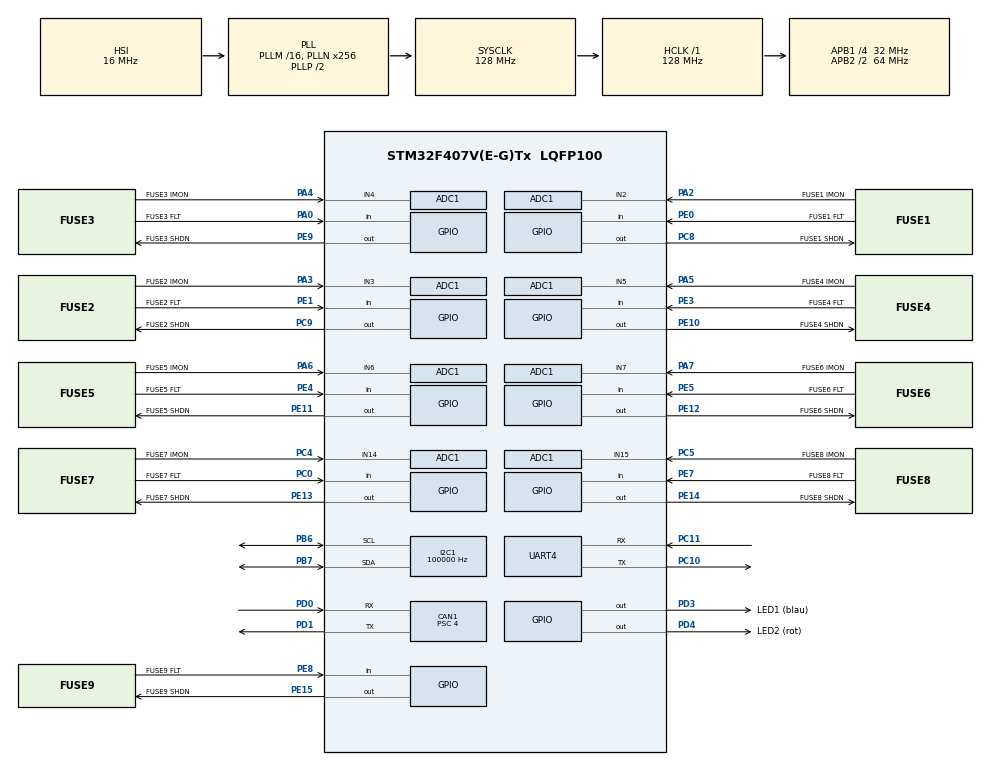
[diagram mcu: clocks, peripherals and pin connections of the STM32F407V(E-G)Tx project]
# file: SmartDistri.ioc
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ADC1.Channel-10\#ChannelRegularConversion=ADC_CHANNEL_14
ADC1.Channel-11\#ChannelRegularConversion=ADC_CHANNEL_15
ADC1.Channel-4\#ChannelRegularConversion=ADC_CHANNEL_2
ADC1.Channel-5\#ChannelRegularConversion=ADC_CHANNEL_3
ADC1.Channel-6\#ChannelRegularConversion=ADC_CHANNEL_4
ADC1.Channel-7\#ChannelRegularConversion=ADC_CHANNEL_5
ADC1.Channel-8\#ChannelRegularConversion=ADC_CHANNEL_6
ADC1.Channel-9\#ChannelRegularConversion=ADC_CHANNEL_7
ADC1.ClockPrescaler=ADC_CLOCK_SYNC_PCLK_DIV8
ADC1.ContinuousConvMode=ENABLE
ADC1.DMAContinuousRequests=ENABLE
ADC1.DiscontinuousConvMode=DISABLE
ADC1.EOCSelection=ADC_EOC_SEQ_CONV
ADC1.NbrOfConversion=8
ADC1.NbrOfConversionFlag=1
ADC1.Rank-10\#ChannelRegularConversion=7
ADC1.Rank-11\#ChannelRegularConversion=8
ADC1.Rank-4\#ChannelRegularConversion=1
ADC1.Rank-5\#ChannelRegularConversion=2
ADC1.Rank-6\#ChannelRegularConversion=3
ADC1.Rank-7\#ChannelRegularConversion=4
ADC1.Rank-8\#ChannelRegularConversion=5
ADC1.Rank-9\#ChannelRegularConversion=6
ADC1.SamplingTime-10\#ChannelRegularConversion=ADC_SAMPLETIME_3CYCLES
ADC1.SamplingTime-11\#ChannelRegularConversion=ADC_SAMPLETIME_3CYCLES
ADC1.SamplingTime-4\#ChannelRegularConversion=ADC_SAMPLETIME_3CYCLES
ADC1.SamplingTime-5\#ChannelRegularConversion=ADC_SAMPLETIME_3CYCLES
ADC1.SamplingTime-6\#ChannelRegularConversion=ADC_SAMPLETIME_3CYCLES
ADC1.SamplingTime-7\#ChannelRegularConversion=ADC_SAMPLETIME_3CYCLES
ADC1.SamplingTime-8\#ChannelRegularConversion=ADC_SAMPLETIME_3CYCLES
ADC1.SamplingTime-9\#ChannelRegularConversion=ADC_SAMPLETIME_3CYCLES
ADC1.master=1
CAN1.BS1=CAN_BS1_13TQ
CAN1.BS2=CAN_BS2_2TQ
CAN1.CalculateTimeQuantum=125.0
CAN1.Mode=CAN_MODE_LOOPBACK
CAN1.Prescaler=4
Dma.ADC1.0.Direction=DMA_PERIPH_TO_MEMORY
Dma.ADC1.0.FIFOMode=DMA_FIFOMODE_DISABLE
Dma.ADC1.0.Instance=DMA2_Stream0
Dma.ADC1.0.MemDataAlignment=DMA_MDATAALIGN_WORD
Dma.ADC1.0.MemInc=DMA_MINC_ENABLE
Dma.ADC1.0.Mode=DMA_CIRCULAR
Dma.ADC1.0.PeriphDataAlignment=DMA_PDATAALIGN_WORD
Dma.ADC1.0.PeriphInc=DMA_PINC_DISABLE
Dma.ADC1.0.Priority=DMA_PRIORITY_LOW
Dma.I2C1_RX.1.Direction=DMA_PERIPH_TO_MEMORY
Dma.I2C1_RX.1.FIFOMode=DMA_FIFOMODE_DISABLE
Dma.I2C1_RX.1.Instance=DMA1_Stream0
Dma.I2C1_RX.1.MemDataAlignment=DMA_MDATAALIGN_BYTE
Dma.I2C1_RX.1.MemInc=DMA_MINC_ENABLE
Dma.I2C1_RX.1.Mode=DMA_CIRCULAR
Dma.I2C1_RX.1.PeriphDataAlignment=DMA_PDATAALIGN_BYTE
Dma.I2C1_RX.1.PeriphInc=DMA_PINC_DISABLE
Dma.I2C1_RX.1.Priority=DMA_PRIORITY_LOW
Dma.Request0=ADC1
Dma.Request1=I2C1_RX
I2C1.ClockSpeed=100000
I2C1.I2C_Mode=I2C_Standard
Mcu.Family=STM32F4
Mcu.Name=STM32F407V(E-G)Tx
Mcu.Package=LQFP100
NVIC.CAN1_RX0_IRQn=true\:0\:0\:false\:false\:true\:true\:true
NVIC.CAN1_TX_IRQn=true\:0\:0\:false\:false\:true\:true\:true
NVIC.DMA1_Stream0_IRQn=true\:0\:0\:false\:false\:true\:false\:true
NVIC.DMA2_Stream0_IRQn=true\:0\:0\:false\:false\:true\:false\:true
NVIC.PriorityGroup=NVIC_PRIORITYGROUP_4
NVIC.TIM1_UP_TIM10_IRQn=true\:0\:0\:false\:false\:true\:true\:true
PA0-WKUP.GPIO_Label=FUSE3 FLT
PA0-WKUP.GPIO_PuPd=GPIO_PULLDOWN
PA0-WKUP.Signal=GPIO_Input
PA13.Signal=SYS_JTMS-SWDIO
PA14.Signal=SYS_JTCK-SWCLK
PA15.Signal=SYS_JTDI
PA2.GPIO_Label=FUSE1 IMON
PA2.Signal=ADCx_IN2
PA3.GPIO_Label=FUSE2 IMON
PA3.Signal=ADCx_IN3
PA4.GPIO_Label=FUSE3 IMON
PA4.Signal=ADCx_IN4
PA5.GPIO_Label=FUSE4 IMON
PA5.Signal=ADCx_IN5
PA6.GPIO_Label=FUSE5 IMON
PA6.Signal=ADCx_IN6
PA7.GPIO_Label=FUSE6 IMON
PA7.Signal=ADCx_IN7
PB6.Mode=I2C
PB6.Signal=I2C1_SCL
PB7.Mode=I2C
PB7.Signal=I2C1_SDA
PC0.GPIO_Label=FUSE7 FLT
PC0.GPIO_PuPd=GPIO_PULLDOWN
PC0.Signal=GPIO_Input
PC10.Mode=Asynchronous
PC10.Signal=UART4_TX
PC11.Mode=Asynchronous
PC11.Signal=UART4_RX
PC4.GPIO_Label=FUSE7 IMON
PC4.Signal=ADCx_IN14
PC5.GPIO_Label=FUSE8 IMON
PC5.Signal=ADCx_IN15
PC8.GPIO_Label=FUSE1 SHDN
PC8.Signal=GPIO_Output
PC9.GPIO_Label=FUSE2 SHDN
PC9.Signal=GPIO_Output
PD0.Mode=Master
PD0.Signal=CAN1_RX
PD1.Mode=Master
PD1.Signal=CAN1_TX
PD3.GPIO_Label=LED1 (blau)
PD3.Signal=GPIO_Output
PD4.GPIO_Label=LED2 (rot)
PD4.Signal=GPIO_Output
PE0.GPIO_Label=FUSE1 FLT
PE0.GPIO_PuPd=GPIO_PULLDOWN
PE0.Signal=GPIO_Input
PE1.GPIO_Label=FUSE2 FLT
PE1.GPIO_PuPd=GPIO_PULLDOWN
PE1.Signal=GPIO_Input
PE10.GPIO_Label=FUSE4 SHDN
PE10.Signal=GPIO_Output
PE11.GPIO_Label=FUSE5 SHDN
PE11.GPIO_PuPd=GPIO_NOPULL
PE11.PinState=GPIO_PIN_SET
PE11.Signal=GPIO_Output
PE12.GPIO_Label=FUSE6 SHDN
PE12.Signal=GPIO_Output
PE13.GPIO_Label=FUSE7 SHDN
PE13.Signal=GPIO_Output
PE14.GPIO_Label=FUSE8 SHDN
PE14.Signal=GPIO_Output
PE15.GPIO_Label=FUSE9 SHDN
PE15.Signal=GPIO_Output
PE3.GPIO_Label=FUSE4 FLT
PE3.GPIO_PuPd=GPIO_PULLDOWN
PE3.Signal=GPIO_Input
PE4.GPIO_Label=FUSE5 FLT
PE4.GPIO_PuPd=GPIO_PULLDOWN
PE4.Signal=GPIO_Input
PE5.GPIO_Label=FUSE6 FLT
PE5.GPIO_PuPd=GPIO_PULLDOWN
PE5.Signal=GPIO_Input
PE7.GPIO_Label=FUSE8 FLT
PE7.GPIO_PuPd=GPIO_PULLDOWN
PE7.Signal=GPIO_Input
PE8.GPIO_Label=FUSE9 FLT
PE8.Signal=GPIO_Input
PE9.GPIO_Label=FUSE3 SHDN
PE9.Signal=GPIO_Output
ProjectManager.HeapSize=0x200
ProjectManager.StackSize=0x400
ProjectManager.TargetToolchain=STM32CubeIDE
RCC.48MHZClocksFreq_Value=64000000
RCC.AHBFreq_Value=128000000
RCC.APB1CLKDivider=RCC_HCLK_DIV4
RCC.APB1Freq_Value=32000000
RCC.APB1TimFreq_Value=64000000
RCC.APB2CLKDivider=RCC_HCLK_DIV2
RCC.APB2Freq_Value=64000000
RCC.APB2TimFreq_Value=128000000
RCC.CortexFreq_Value=128000000
RCC.HCLKFreq_Value=128000000
RCC.HSE_VALUE=25000000
RCC.HSI_VALUE=16000000
RCC.LSE_VALUE=32768
RCC.PLLN=256
RCC.SYSCLKFreq_VALUE=128000000
RCC.SYSCLKSource=RCC_SYSCLKSOURCE_PLLCLK
RCC.VCOOutputFreq_Value=256000000
SH.ADCx_IN14.0=ADC1_IN14,IN14
SH.ADCx_IN15.0=ADC1_IN15,IN15
SH.ADCx_IN2.0=ADC1_IN2,IN2
SH.ADCx_IN3.0=ADC1_IN3,IN3
SH.ADCx_IN4.0=ADC1_IN4,IN4
SH.ADCx_IN5.0=ADC1_IN5,IN5
SH.ADCx_IN6.0=ADC1_IN6,IN6
SH.ADCx_IN7.0=ADC1_IN7,IN7
TIM1.Period=400
TIM1.Prescaler=64000
UART4.VirtualMode=Asynchronous
VP_TIM1_VS_ClockSourceINT.Mode=Internal
VP_TIM1_VS_ClockSourceITR.Mode=TriggerSource_ITR0
board=custom

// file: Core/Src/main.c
/* USER CODE BEGIN Header */
/**
  ******************************************************************************
  * @file           : main.c
  * @brief          : Main program body
  ******************************************************************************
  * @attention
  *
  * <h2><center>&copy; Copyright (c) 2020 STMicroelectronics.
  * All rights reserved.</center></h2>
  *
  * This software component is licensed by ST under BSD 3-Clause license,
  * the "License"; You may not use this file except in compliance with the
  * License. You may obtain a copy of the License at:
  *                        opensource.org/licenses/BSD-3-Clause
  *
  ******************************************************************************
  */
/* USER CODE END Header */
#include "main.h"

/* USER CODE BEGIN Includes */
#include "smart_distri.h"
/* USER CODE END Includes */

ADC_HandleTypeDef hadc1;
DMA_HandleTypeDef hdma_adc1;

CAN_HandleTypeDef hcan1;

I2C_HandleTypeDef hi2c1;
DMA_HandleTypeDef hdma_i2c1_rx;

TIM_HandleTypeDef htim1;

UART_HandleTypeDef huart4;

void SystemClock_Config(void);
static void MX_GPIO_Init(void);
static void MX_DMA_Init(void);
static void MX_CAN1_Init(void);
static void MX_UART4_Init(void);
static void MX_ADC1_Init(void);
static void MX_I2C1_Init(void);
static void MX_TIM1_Init(void);

int main(void)
{

  /* MCU Configuration--------------------------------------------------------*/

  /* Reset of all peripherals, Initializes the Flash interface and the Systick. */
  HAL_Init();

  /* Configure the system clock */
  SystemClock_Config();

  /* Initialize all configured peripherals */
  MX_GPIO_Init();
  MX_DMA_Init();
  MX_CAN1_Init();
  MX_UART4_Init();
  MX_ADC1_Init();
  MX_I2C1_Init();
  MX_TIM1_Init();
  /* USER CODE BEGIN 2 */
  Setup();
  /* USER CODE END 2 */

  /* Infinite loop */
  while (1)
  {

  }
}

void SystemClock_Config(void)
{
  RCC_OscInitTypeDef RCC_OscInitStruct = {0};
  RCC_ClkInitTypeDef RCC_ClkInitStruct = {0};

  /** Configure the main internal regulator output voltage
  */
  __HAL_RCC_PWR_CLK_ENABLE();
  __HAL_PWR_VOLTAGESCALING_CONFIG(PWR_REGULATOR_VOLTAGE_SCALE1);
  /** Initializes the RCC Oscillators according to the specified parameters
  * in the RCC_OscInitTypeDef structure.
  */
  RCC_OscInitStruct.OscillatorType = RCC_OSCILLATORTYPE_HSI;
  RCC_OscInitStruct.HSIState = RCC_HSI_ON;
  RCC_OscInitStruct.HSICalibrationValue = RCC_HSICALIBRATION_DEFAULT;
  RCC_OscInitStruct.PLL.PLLState = RCC_PLL_ON;
  RCC_OscInitStruct.PLL.PLLSource = RCC_PLLSOURCE_HSI;
  RCC_OscInitStruct.PLL.PLLM = 16;
  RCC_OscInitStruct.PLL.PLLN = 256;
  RCC_OscInitStruct.PLL.PLLP = RCC_PLLP_DIV2;
  RCC_OscInitStruct.PLL.PLLQ = 4;
  if (HAL_RCC_OscConfig(&RCC_OscInitStruct) != HAL_OK)
  {
    Error_Handler();
  }
  /** Initializes the CPU, AHB and APB buses clocks
  */
  RCC_ClkInitStruct.ClockType = RCC_CLOCKTYPE_HCLK|RCC_CLOCKTYPE_SYSCLK
                              |RCC_CLOCKTYPE_PCLK1|RCC_CLOCKTYPE_PCLK2;
  RCC_ClkInitStruct.SYSCLKSource = RCC_SYSCLKSOURCE_PLLCLK;
  RCC_ClkInitStruct.AHBCLKDivider = RCC_SYSCLK_DIV1;
  RCC_ClkInitStruct.APB1CLKDivider = RCC_HCLK_DIV4;
  RCC_ClkInitStruct.APB2CLKDivider = RCC_HCLK_DIV2;

  if (HAL_RCC_ClockConfig(&RCC_ClkInitStruct, FLASH_LATENCY_4) != HAL_OK)
  {
    Error_Handler();
  }
}

static void MX_ADC1_Init(void)
{

  ADC_ChannelConfTypeDef sConfig = {0};

  /** Configure the global features of the ADC (Clock, Resolution, Data Alignment and number of conversion)
  */
  hadc1.Instance = ADC1;
  hadc1.Init.ClockPrescaler = ADC_CLOCK_SYNC_PCLK_DIV8;
  hadc1.Init.Resolution = ADC_RESOLUTION_12B;
  hadc1.Init.ScanConvMode = ENABLE;
  hadc1.Init.ContinuousConvMode = ENABLE;
  hadc1.Init.DiscontinuousConvMode = DISABLE;
  hadc1.Init.ExternalTrigConvEdge = ADC_EXTERNALTRIGCONVEDGE_NONE;
  hadc1.Init.ExternalTrigConv = ADC_SOFTWARE_START;
  hadc1.Init.DataAlign = ADC_DATAALIGN_RIGHT;
  hadc1.Init.NbrOfConversion = 8;
  hadc1.Init.DMAContinuousRequests = ENABLE;
  hadc1.Init.EOCSelection = ADC_EOC_SEQ_CONV;
  if (HAL_ADC_Init(&hadc1) != HAL_OK)
  {
    Error_Handler();
  }
  /** Configure for the selected ADC regular channel its corresponding rank in the sequencer and its sample time.
  */
  sConfig.Channel = ADC_CHANNEL_2;
  sConfig.Rank = 1;
  sConfig.SamplingTime = ADC_SAMPLETIME_3CYCLES;
  if (HAL_ADC_ConfigChannel(&hadc1, &sConfig) != HAL_OK)
  {
    Error_Handler();
  }
  /** Configure for the selected ADC regular channel its corresponding rank in the sequencer and its sample time.
  */
  sConfig.Channel = ADC_CHANNEL_3;
  sConfig.Rank = 2;
  if (HAL_ADC_ConfigChannel(&hadc1, &sConfig) != HAL_OK)
  {
    Error_Handler();
  }
  /** Configure for the selected ADC regular channel its corresponding rank in the sequencer and its sample time.
  */
  sConfig.Channel = ADC_CHANNEL_4;
  sConfig.Rank = 3;
  if (HAL_ADC_ConfigChannel(&hadc1, &sConfig) != HAL_OK)
  {
    Error_Handler();
  }
  /** Configure for the selected ADC regular channel its corresponding rank in the sequencer and its sample time.
  */
  sConfig.Channel = ADC_CHANNEL_5;
  sConfig.Rank = 4;
  if (HAL_ADC_ConfigChannel(&hadc1, &sConfig) != HAL_OK)
  {
    Error_Handler();
  }
  /** Configure for the selected ADC regular channel its corresponding rank in the sequencer and its sample time.
  */
  sConfig.Channel = ADC_CHANNEL_6;
  sConfig.Rank = 5;
  if (HAL_ADC_ConfigChannel(&hadc1, &sConfig) != HAL_OK)
  {
    Error_Handler();
  }
  /** Configure for the selected ADC regular channel its corresponding rank in the sequencer and its sample time.
  */
  sConfig.Channel = ADC_CHANNEL_7;
  sConfig.Rank = 6;
  if (HAL_ADC_ConfigChannel(&hadc1, &sConfig) != HAL_OK)
  {
    Error_Handler();
  }
  /** Configure for the selected ADC regular channel its corresponding rank in the sequencer and its sample time.
  */
  sConfig.Channel = ADC_CHANNEL_14;
  sConfig.Rank = 7;
  if (HAL_ADC_ConfigChannel(&hadc1, &sConfig) != HAL_OK)
  {
    Error_Handler();
  }
  /** Configure for the selected ADC regular channel its corresponding rank in the sequencer and its sample time.
  */
  sConfig.Channel = ADC_CHANNEL_15;
  sConfig.Rank = 8;
  if (HAL_ADC_ConfigChannel(&hadc1, &sConfig) != HAL_OK)
  {
    Error_Handler();
  }

}

static void MX_CAN1_Init(void)
{

  hcan1.Instance = CAN1;
  hcan1.Init.Prescaler = 4;
  hcan1.Init.Mode = CAN_MODE_LOOPBACK;
  hcan1.Init.SyncJumpWidth = CAN_SJW_1TQ;
  hcan1.Init.TimeSeg1 = CAN_BS1_13TQ;
  hcan1.Init.TimeSeg2 = CAN_BS2_2TQ;
  hcan1.Init.TimeTriggeredMode = DISABLE;
  hcan1.Init.AutoBusOff = DISABLE;
  hcan1.Init.AutoWakeUp = DISABLE;
  hcan1.Init.AutoRetransmission = DISABLE;
  hcan1.Init.ReceiveFifoLocked = DISABLE;
  hcan1.Init.TransmitFifoPriority = DISABLE;
  if (HAL_CAN_Init(&hcan1) != HAL_OK)
  {
    Error_Handler();
  }

}

static void MX_I2C1_Init(void)
{

  hi2c1.Instance = I2C1;
  hi2c1.Init.ClockSpeed = 100000;
  hi2c1.Init.DutyCycle = I2C_DUTYCYCLE_2;
  hi2c1.Init.OwnAddress1 = 0;
  hi2c1.Init.AddressingMode = I2C_ADDRESSINGMODE_7BIT;
  hi2c1.Init.DualAddressMode = I2C_DUALADDRESS_DISABLE;
  hi2c1.Init.OwnAddress2 = 0;
  hi2c1.Init.GeneralCallMode = I2C_GENERALCALL_DISABLE;
  hi2c1.Init.NoStretchMode = I2C_NOSTRETCH_DISABLE;
  if (HAL_I2C_Init(&hi2c1) != HAL_OK)
  {
    Error_Handler();
  }

}

static void MX_TIM1_Init(void)
{

  TIM_ClockConfigTypeDef sClockSourceConfig = {0};
  TIM_SlaveConfigTypeDef sSlaveConfig = {0};
  TIM_MasterConfigTypeDef sMasterConfig = {0};

  htim1.Instance = TIM1;
  htim1.Init.Prescaler = 64000;
  htim1.Init.CounterMode = TIM_COUNTERMODE_UP;
  htim1.Init.Period = 400;
  htim1.Init.ClockDivision = TIM_CLOCKDIVISION_DIV1;
  htim1.Init.RepetitionCounter = 0;
  htim1.Init.AutoReloadPreload = TIM_AUTORELOAD_PRELOAD_DISABLE;
  if (HAL_TIM_Base_Init(&htim1) != HAL_OK)
  {
    Error_Handler();
  }
  sClockSourceConfig.ClockSource = TIM_CLOCKSOURCE_INTERNAL;
  if (HAL_TIM_ConfigClockSource(&htim1, &sClockSourceConfig) != HAL_OK)
  {
    Error_Handler();
  }
  sSlaveConfig.SlaveMode = TIM_SLAVEMODE_DISABLE;
  sSlaveConfig.InputTrigger = TIM_TS_ITR0;
  if (HAL_TIM_SlaveConfigSynchro(&htim1, &sSlaveConfig) != HAL_OK)
  {
    Error_Handler();
  }
  sMasterConfig.MasterOutputTrigger = TIM_TRGO_RESET;
  sMasterConfig.MasterSlaveMode = TIM_MASTERSLAVEMODE_DISABLE;
  if (HAL_TIMEx_MasterConfigSynchronization(&htim1, &sMasterConfig) != HAL_OK)
  {
    Error_Handler();
  }

}

static void MX_UART4_Init(void)
{

  huart4.Instance = UART4;
  huart4.Init.BaudRate = 115200;
  huart4.Init.WordLength = UART_WORDLENGTH_8B;
  huart4.Init.StopBits = UART_STOPBITS_1;
  huart4.Init.Parity = UART_PARITY_NONE;
  huart4.Init.Mode = UART_MODE_TX_RX;
  huart4.Init.HwFlowCtl = UART_HWCONTROL_NONE;
  huart4.Init.OverSampling = UART_OVERSAMPLING_16;
  if (HAL_UART_Init(&huart4) != HAL_OK)
  {
    Error_Handler();
  }

}

static void MX_DMA_Init(void)
{

  /* DMA controller clock enable */
  __HAL_RCC_DMA2_CLK_ENABLE();
  __HAL_RCC_DMA1_CLK_ENABLE();

  /* DMA interrupt init */
  /* DMA1_Stream0_IRQn interrupt configuration */
  HAL_NVIC_SetPriority(DMA1_Stream0_IRQn, 0, 0);
  HAL_NVIC_EnableIRQ(DMA1_Stream0_IRQn);
  /* DMA2_Stream0_IRQn interrupt configuration */
  HAL_NVIC_SetPriority(DMA2_Stream0_IRQn, 0, 0);
  HAL_NVIC_EnableIRQ(DMA2_Stream0_IRQn);

}

static void MX_GPIO_Init(void)
{
  GPIO_InitTypeDef GPIO_InitStruct = {0};

  /* GPIO Ports Clock Enable */
  __HAL_RCC_GPIOE_CLK_ENABLE();
  __HAL_RCC_GPIOC_CLK_ENABLE();
  __HAL_RCC_GPIOA_CLK_ENABLE();
  __HAL_RCC_GPIOD_CLK_ENABLE();
  __HAL_RCC_GPIOB_CLK_ENABLE();

  /*Configure GPIO pin Output Level */
  HAL_GPIO_WritePin(GPIOE, FUSE3_SHDN_Pin|FUSE4_SHDN_Pin|FUSE6_SHDN_Pin|FUSE7_SHDN_Pin
                          |FUSE8_SHDN_Pin|FUSE9_SHDN_Pin, GPIO_PIN_RESET);

  /*Configure GPIO pin Output Level */
  HAL_GPIO_WritePin(FUSE5_SHDN_GPIO_Port, FUSE5_SHDN_Pin, GPIO_PIN_SET);

  /*Configure GPIO pin Output Level */
  HAL_GPIO_WritePin(GPIOC, FUSE1_SHDN_Pin|FUSE2_SHDN_Pin, GPIO_PIN_RESET);

  /*Configure GPIO pin Output Level */
  HAL_GPIO_WritePin(GPIOD, LED1_Pin|LED2_Pin, GPIO_PIN_RESET);

  /*Configure GPIO pins : FUSE4_FLT_Pin FUSE5_FLT_Pin FUSE6_FLT_Pin FUSE8_FLT_Pin
                           FUSE1_FLT_Pin FUSE2_FLT_Pin */
  GPIO_InitStruct.Pin = FUSE4_FLT_Pin|FUSE5_FLT_Pin|FUSE6_FLT_Pin|FUSE8_FLT_Pin
                          |FUSE1_FLT_Pin|FUSE2_FLT_Pin;
  GPIO_InitStruct.Mode = GPIO_MODE_INPUT;
  GPIO_InitStruct.Pull = GPIO_PULLDOWN;
  HAL_GPIO_Init(GPIOE, &GPIO_InitStruct);

  /*Configure GPIO pin : FUSE7_FLT_Pin */
  GPIO_InitStruct.Pin = FUSE7_FLT_Pin;
  GPIO_InitStruct.Mode = GPIO_MODE_INPUT;
  GPIO_InitStruct.Pull = GPIO_PULLDOWN;
  HAL_GPIO_Init(FUSE7_FLT_GPIO_Port, &GPIO_InitStruct);

  /*Configure GPIO pin : FUSE3_FLT_Pin */
  GPIO_InitStruct.Pin = FUSE3_FLT_Pin;
  GPIO_InitStruct.Mode = GPIO_MODE_INPUT;
  GPIO_InitStruct.Pull = GPIO_PULLDOWN;
  HAL_GPIO_Init(FUSE3_FLT_GPIO_Port, &GPIO_InitStruct);

  /*Configure GPIO pin : FUSE9_FLT_Pin */
  GPIO_InitStruct.Pin = FUSE9_FLT_Pin;
  GPIO_InitStruct.Mode = GPIO_MODE_INPUT;
  GPIO_InitStruct.Pull = GPIO_NOPULL;
  HAL_GPIO_Init(FUSE9_FLT_GPIO_Port, &GPIO_InitStruct);

  /*Configure GPIO pins : FUSE3_SHDN_Pin FUSE4_SHDN_Pin FUSE5_SHDN_Pin FUSE6_SHDN_Pin
                           FUSE7_SHDN_Pin FUSE8_SHDN_Pin FUSE9_SHDN_Pin */
  GPIO_InitStruct.Pin = FUSE3_SHDN_Pin|FUSE4_SHDN_Pin|FUSE5_SHDN_Pin|FUSE6_SHDN_Pin
                          |FUSE7_SHDN_Pin|FUSE8_SHDN_Pin|FUSE9_SHDN_Pin;
  GPIO_InitStruct.Mode = GPIO_MODE_OUTPUT_PP;
  GPIO_InitStruct.Pull = GPIO_NOPULL;
  GPIO_InitStruct.Speed = GPIO_SPEED_FREQ_LOW;
  HAL_GPIO_Init(GPIOE, &GPIO_InitStruct);

  /*Configure GPIO pins : FUSE1_SHDN_Pin FUSE2_SHDN_Pin */
  GPIO_InitStruct.Pin = FUSE1_SHDN_Pin|FUSE2_SHDN_Pin;
  GPIO_InitStruct.Mode = GPIO_MODE_OUTPUT_PP;
  GPIO_InitStruct.Pull = GPIO_NOPULL;
  GPIO_InitStruct.Speed = GPIO_SPEED_FREQ_LOW;
  HAL_GPIO_Init(GPIOC, &GPIO_InitStruct);

  /*Configure GPIO pins : LED1_Pin LED2_Pin */
  GPIO_InitStruct.Pin = LED1_Pin|LED2_Pin;
  GPIO_InitStruct.Mode = GPIO_MODE_OUTPUT_PP;
  GPIO_InitStruct.Pull = GPIO_NOPULL;
  GPIO_InitStruct.Speed = GPIO_SPEED_FREQ_LOW;
  HAL_GPIO_Init(GPIOD, &GPIO_InitStruct);

}

void Error_Handler(void)
{
}

/************************ (C) COPYRIGHT STMicroelectronics *****END OF FILE****/
